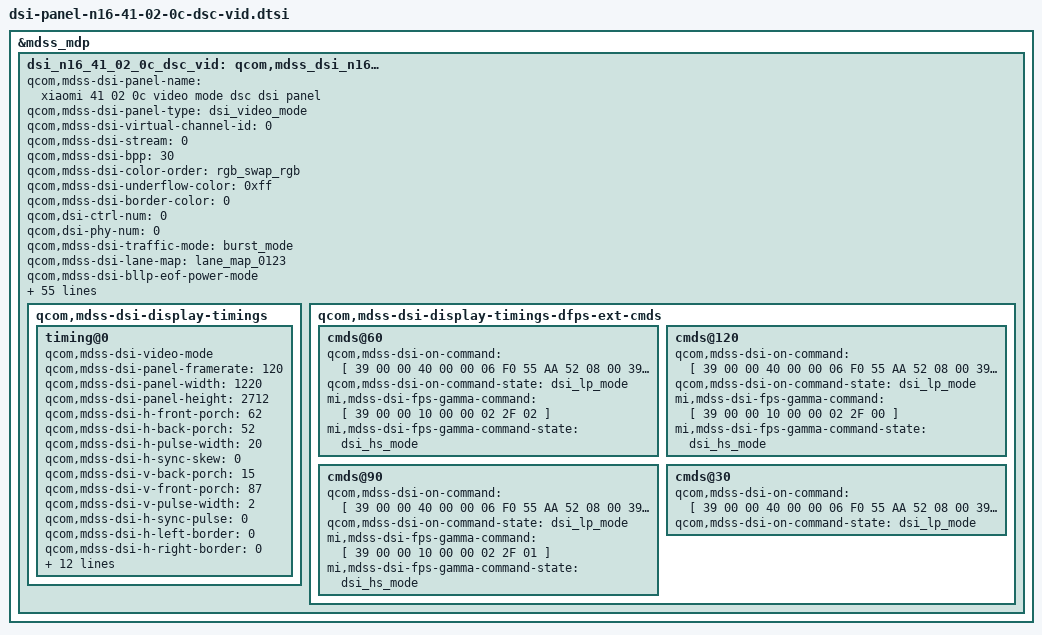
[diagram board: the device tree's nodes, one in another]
&mdss_mdp {
	dsi_n16_41_02_0c_dsc_vid: qcom,mdss_dsi_n16_41_02_0c_dsc_vid {
		qcom,mdss-dsi-panel-name = "xiaomi 41 02 0c video mode dsc dsi panel";
		qcom,mdss-dsi-panel-type = "dsi_video_mode";
		qcom,mdss-dsi-virtual-channel-id = <0>;
		qcom,mdss-dsi-stream = <0>;
		qcom,mdss-dsi-bpp = <30>;
		qcom,mdss-dsi-color-order = "rgb_swap_rgb";
		qcom,mdss-dsi-underflow-color = <0xff>;
		qcom,mdss-dsi-border-color = <0>;

		qcom,dsi-ctrl-num = <0>;
		qcom,dsi-phy-num = <0>;

		qcom,mdss-dsi-traffic-mode = "burst_mode";
		qcom,mdss-dsi-lane-map = "lane_map_0123";
		qcom,mdss-dsi-bllp-eof-power-mode;
		qcom,mdss-dsi-bllp-power-mode;
		qcom,mdss-dsi-lane-0-state;
		qcom,mdss-dsi-lane-1-state;
		qcom,mdss-dsi-lane-2-state;
		qcom,mdss-dsi-lane-3-state;
		qcom,mdss-dsi-dma-trigger = "trigger_sw";
		qcom,mdss-dsi-mdp-trigger = "none";
		qcom,mdss-dsi-reset-sequence =<1 11>, <0 1>, <1 11>;
		qcom,mdss-pan-physical-width-dimension = <70>;
		qcom,mdss-pan-physical-height-dimension = <154>;

		qcom,mdss-dsi-tx-eot-append;
		qcom,mdss-dsi-lp11-init;
		qcom,mdss-dsi-bl-inverted-dbv;
		qcom,bl-update-flag = "delay_until_first_frame";

		qcom,mdss-dsi-panel-hdr-enabled;
		qcom,mdss-dsi-panel-hdr-color-primaries = <14500 15500 32000 17000 15500 30000 8000 3000>;
		qcom,mdss-dsi-panel-peak-brightness = <4200000>;
		qcom,mdss-dsi-panel-blackness-level = <3230>;

		qcom,mdss-dsi-pan-enable-dynamic-fps;
		qcom,mdss-dsi-pan-fps-update =
				"dfps_immediate_porch_mode_vfp";
		qcom,dsi-supported-dfps-list = <60 120 90>;

		mi,mdss-dsi-panel-cell-id-read-command = [06 01 00 02 00 00 01 AC];
		mi,mdss-dsi-panel-cell-id-read-command-state = "dsi_hs_mode";
		mi,mdss-dsi-panel-cell-id-read-length = <18>;

		mi,mdss-dsi-panel-wp-read-command = [06 01 00 02 00 00 01 AC];
		mi,mdss-dsi-panel-wp-read-command-state = "dsi_hs_mode";
		mi,mdss-dsi-panel-wp-read-length = <3>;

        mi,mdss-dsi-panel-wp-read-pre-tx-command = [39 00 00 00 00 00 02 6F 18];
        mi,mdss-dsi-panel-wp-read-pre-tx-command-state = "dsi_hs_mode";

qcom,mdss-dsi-display-timings {
			timing@0{
				qcom,mdss-dsi-video-mode;
				qcom,mdss-dsi-panel-framerate = <120>;
				qcom,mdss-dsi-panel-width = <1220>;
				qcom,mdss-dsi-panel-height = <2712>;
				qcom,mdss-dsi-h-front-porch = <62>;
				qcom,mdss-dsi-h-back-porch = <52>;
				qcom,mdss-dsi-h-pulse-width = <20>;
				qcom,mdss-dsi-h-sync-skew = <0>;
				qcom,mdss-dsi-v-back-porch = <15>;
				qcom,mdss-dsi-v-front-porch = <87>;
				qcom,mdss-dsi-v-pulse-width = <2>;
				qcom,mdss-dsi-h-sync-pulse = <0>;
				qcom,mdss-dsi-h-left-border = <0>;
				qcom,mdss-dsi-h-right-border = <0>;
				qcom,mdss-dsi-v-top-border = <0>;
				qcom,mdss-dsi-v-bottom-border = <0>;

				qcom,compression-mode = "dsc";
				qcom,mdss-dsc-version = <0x12>;
				qcom,mdss-dsc-scr-version = <0x0>;
				qcom,mdss-dsc-slice-height = <12>;
				qcom,mdss-dsc-slice-width = <610>;
				qcom,mdss-dsc-slice-per-pkt = <2>;
				qcom,mdss-dsc-bit-per-component = <10>;
				qcom,mdss-dsc-bit-per-pixel = <8>;
				qcom,mdss-dsc-block-prediction-enable;
				qcom,mdss-dsi-panel-clockrate = <1098000000>;
			};
		};

qcom,mdss-dsi-display-timings-dfps-ext-cmds {
			cmds@60{
				qcom,mdss-dsi-on-command = [
					39 00 00 40 00 00 06 F0 55 AA 52 08 00
					39 00 00 40 00 00 02 6F 14
					39 00 00 40 00 00 1B B4 00 12 00 12 00 12 00 12 00 12 00 12 00 12 00 12 00 12 00 12 00 12 00 12 00 12
					39 00 00 40 00 00 02 6F 37
					39 00 00 00 00 00 04 DF 00 00 12
					39 00 00 40 00 00 05 FF AA 55 A5 80
					39 00 00 40 00 00 02 6F 18
					39 00 00 40 00 00 02 F4 73
					39 00 00 40 00 00 02 6F 2A
					39 00 00 40 00 00 02 F4 08
					39 00 00 40 00 00 02 6F 1A
					39 00 00 40 00 00 02 FE 00
					39 00 00 40 00 00 02 6F 46
					39 00 00 40 00 00 03 F4 07 09
					39 00 00 40 00 00 02 6F 4A
					39 00 00 40 00 00 03 F4 08 0A
					39 00 00 40 00 00 02 6F 56
					39 00 00 40 00 00 03 F4 44 44
					39 00 00 40 00 00 02 6F 0B
					39 00 00 00 00 00 02 F5 02
					39 00 00 40 00 00 06 F0 55 AA 52 08 08
					39 00 00 40 00 00 02 6F CE
					39 00 00 40 00 00 02 BC 01
					39 00 00 40 00 00 02 6F CF
					39 00 00 40 00 00 09 BC 01 11 00 B6 01 11 00 44
					39 00 00 00 00 00 02 E0 F3
					39 00 00 40 00 00 05 FF AA 55 A5 81
					39 00 00 40 00 00 02 6F 3C
					39 00 00 40 00 00 02 F5 87
					39 00 00 40 00 00 02 17 03
					39 00 00 40 00 00 02 71 00
					39 00 00 40 00 00 09 8D 00 00 04 C3 00 00 0A 97
					39 00 00 40 00 00 06 88 81 02 61 09 85
					39 00 00 40 00 00 05 2A 00 00 04 C3
					39 00 00 40 00 00 05 2B 00 00 0A 97
					39 00 00 40 00 00 02 03 00
					39 00 00 40 00 00 02 90 03
					39 00 00 40 00 00 02 6F 01
					39 00 00 40 00 00 02 90 43
					39 00 00 40 00 00 13 91 AB 28 00 0C C2 00 02 32 01 31 00 08 08 BB 07 7B 10 F0
					39 00 00 40 00 00 02 2F 02
					39 00 00 40 00 00 02 26 00
					39 00 00 40 00 00 03 5F 05 00
					39 00 00 40 00 00 02 53 20
					39 00 00 40 00 00 0D 3B 00 11 00 57 00 11 03 C7 00 11 0B 57
					39 00 00 40 00 00 02 6F 10
					39 00 00 40 00 00 05 3B 00 11 00 57
					39 00 00 40 00 00 02 35 00
					39 00 00 00 00 00 03 51 00 00
					39 00 00 40 00 00 06 F0 55 AA 52 08 00
					39 00 00 40 00 00 02 6F 13
					39 00 00 40 00 00 02 BE 45
					39 00 00 40 00 00 02 6F 19
					39 00 00 40 00 00 05 BE 10 91 00 AB
					39 00 00 40 00 00 02 6F 0D
					39 00 00 00 00 00 02 D8 02
					39 00 00 40 00 00 06 F0 55 AA 52 08 07
					15 00 00 40 00 00 02 C0 87
					15 00 00 40 00 00 02 6F 03
					39 00 00 00 00 00 0F C0 00 00 00 00 55 00 00 00 00 00 00 00 00 00
					39 00 00 00 78 00 02 11 00
					39 00 00 00 00 00 02 29 00
				];
				qcom,mdss-dsi-on-command-state = "dsi_lp_mode";

				mi,mdss-dsi-fps-gamma-command = [
					39 00 00 10 00 00 02 2F 02
				];
				mi,mdss-dsi-fps-gamma-command-state = "dsi_hs_mode";

				#include "dsi-panel-n16-41-02-0c-dsc-vid-common.dtsi"
			};
			cmds@120{
				qcom,mdss-dsi-on-command = [
					39 00 00 40 00 00 06 F0 55 AA 52 08 00
					39 00 00 40 00 00 02 6F 14
					39 00 00 40 00 00 1B B4 00 12 00 12 00 12 00 12 00 12 00 12 00 12 00 12 00 12 00 12 00 12 00 12 00 12
					39 00 00 40 00 00 02 6F 37
					39 00 00 00 00 00 04 DF 00 00 12
					39 00 00 40 00 00 05 FF AA 55 A5 80
					39 00 00 40 00 00 02 6F 18
					39 00 00 40 00 00 02 F4 73
					39 00 00 40 00 00 02 6F 2A
					39 00 00 40 00 00 02 F4 08
					39 00 00 40 00 00 02 6F 1A
					39 00 00 40 00 00 02 FE 00
					39 00 00 40 00 00 02 6F 46
					39 00 00 40 00 00 03 F4 07 09
					39 00 00 40 00 00 02 6F 4A
					39 00 00 40 00 00 03 F4 08 0A
					39 00 00 40 00 00 02 6F 56
					39 00 00 40 00 00 03 F4 44 44
					39 00 00 40 00 00 02 6F 0B
					39 00 00 00 00 00 02 F5 02
					39 00 00 40 00 00 06 F0 55 AA 52 08 08
					39 00 00 40 00 00 02 6F CE
					39 00 00 40 00 00 02 BC 01
					39 00 00 40 00 00 02 6F CF
					39 00 00 40 00 00 09 BC 01 11 00 B6 01 11 00 44
					39 00 00 00 00 00 02 E0 F3
					39 00 00 40 00 00 05 FF AA 55 A5 81
					39 00 00 40 00 00 02 6F 3C
					39 00 00 40 00 00 02 F5 87
					39 00 00 40 00 00 02 17 03
					39 00 00 40 00 00 02 71 00
					39 00 00 40 00 00 09 8D 00 00 04 C3 00 00 0A 97
					39 00 00 40 00 00 06 88 81 02 61 09 85
					39 00 00 40 00 00 05 2A 00 00 04 C3
					39 00 00 40 00 00 05 2B 00 00 0A 97
					39 00 00 40 00 00 02 03 00
					39 00 00 40 00 00 02 90 03
					39 00 00 40 00 00 02 6F 01
					39 00 00 40 00 00 02 90 43
					39 00 00 40 00 00 13 91 AB 28 00 0C C2 00 02 32 01 31 00 08 08 BB 07 7B 10 F0
					39 00 00 40 00 00 02 2F 00
					39 00 00 40 00 00 02 26 00
					39 00 00 40 00 00 03 5F 05 00
					39 00 00 40 00 00 02 53 20
					39 00 00 40 00 00 0D 3B 00 11 00 57 00 11 03 C7 00 11 0B 57
					39 00 00 40 00 00 02 6F 10
					39 00 00 40 00 00 05 3B 00 11 00 57
					39 00 00 40 00 00 02 35 00
					39 00 00 00 00 00 03 51 00 00
					39 00 00 40 00 00 06 F0 55 AA 52 08 00
					39 00 00 40 00 00 02 6F 13
					39 00 00 40 00 00 02 BE 45
					39 00 00 40 00 00 02 6F 19
					39 00 00 40 00 00 05 BE 10 91 00 AB
					39 00 00 40 00 00 02 6F 0D
					39 00 00 00 00 00 02 D8 02
					39 00 00 40 00 00 06 F0 55 AA 52 08 07 15 00 00 40 00 00 02 C0 87 15 00 00 40 00 00 02 6F 03
					39 00 00 00 00 00 0F C0 00 00 00 00 55 00 00 00 00 00 00 00 00 00
					39 00 00 00 78 00 02 11 00
					39 00 00 00 00 00 02 29 00
				];
				qcom,mdss-dsi-on-command-state = "dsi_lp_mode";

				mi,mdss-dsi-fps-gamma-command = [
					39 00 00 10 00 00 02 2F 00
				];
				mi,mdss-dsi-fps-gamma-command-state = "dsi_hs_mode";

				#include "dsi-panel-n16-41-02-0c-dsc-vid-common.dtsi"
			};
			cmds@90{
				qcom,mdss-dsi-on-command = [
					39 00 00 40 00 00 06 F0 55 AA 52 08 00
					39 00 00 40 00 00 02 6F 14
					39 00 00 40 00 00 1B B4 00 12 00 12 00 12 00 12 00 12 00 12 00 12 00 12 00 12 00 12 00 12 00 12 00 12
					39 00 00 40 00 00 02 6F 37
					39 00 00 00 00 00 04 DF 00 00 12
					39 00 00 40 00 00 05 FF AA 55 A5 80
					39 00 00 40 00 00 02 6F 18
					39 00 00 40 00 00 02 F4 73
					39 00 00 40 00 00 02 6F 2A
					39 00 00 40 00 00 02 F4 08
					39 00 00 40 00 00 02 6F 1A
					39 00 00 40 00 00 02 FE 00
					39 00 00 40 00 00 02 6F 46
					39 00 00 40 00 00 03 F4 07 09
					39 00 00 40 00 00 02 6F 4A
					39 00 00 40 00 00 03 F4 08 0A
					39 00 00 40 00 00 02 6F 56
					39 00 00 40 00 00 03 F4 44 44
					39 00 00 40 00 00 02 6F 0B
					39 00 00 00 00 00 02 F5 02
					39 00 00 40 00 00 06 F0 55 AA 52 08 08
					39 00 00 40 00 00 02 6F CE
					39 00 00 40 00 00 02 BC 01
					39 00 00 40 00 00 02 6F CF
					39 00 00 40 00 00 09 BC 01 11 00 B6 01 11 00 44
					39 00 00 00 00 00 02 E0 F3
					39 00 00 40 00 00 05 FF AA 55 A5 81
					39 00 00 40 00 00 02 6F 3C
					39 00 00 40 00 00 02 F5 87
					39 00 00 40 00 00 02 17 03
					39 00 00 40 00 00 02 71 00
					39 00 00 40 00 00 09 8D 00 00 04 C3 00 00 0A 97
					39 00 00 40 00 00 06 88 81 02 61 09 85
					39 00 00 40 00 00 05 2A 00 00 04 C3
					39 00 00 40 00 00 05 2B 00 00 0A 97
					39 00 00 40 00 00 02 03 00
					39 00 00 40 00 00 02 90 03
					39 00 00 40 00 00 02 6F 01
					39 00 00 40 00 00 02 90 43
					39 00 00 40 00 00 13 91 AB 28 00 0C C2 00 02 32 01 31 00 08 08 BB 07 7B 10 F0
					39 00 00 40 00 00 02 2F 01
					39 00 00 40 00 00 02 26 00
					39 00 00 40 00 00 03 5F 05 00
					39 00 00 40 00 00 02 53 20
					39 00 00 40 00 00 0D 3B 00 11 00 57 00 11 03 C7 00 11 0B 57
					39 00 00 40 00 00 02 6F 10
					39 00 00 40 00 00 05 3B 00 11 00 57
					39 00 00 40 00 00 02 35 00
					39 00 00 00 00 00 03 51 00 00
					39 00 00 40 00 00 06 F0 55 AA 52 08 00
					39 00 00 40 00 00 02 6F 13
					39 00 00 40 00 00 02 BE 45
					39 00 00 40 00 00 02 6F 19
					39 00 00 40 00 00 05 BE 10 91 00 AB
					39 00 00 40 00 00 02 6F 0D
					39 00 00 00 00 00 02 D8 02
					39 00 00 40 00 00 06 F0 55 AA 52 08 07
					15 00 00 40 00 00 02 C0 87
					15 00 00 40 00 00 02 6F 03
					39 00 00 00 00 00 0F C0 00 00 00 00 55 00 00 00 00 00 00 00 00 00
					39 00 00 00 78 00 02 11 00
					39 00 00 00 00 00 02 29 00
				];
				qcom,mdss-dsi-on-command-state = "dsi_lp_mode";

				mi,mdss-dsi-fps-gamma-command = [
					39 00 00 10 00 00 02 2F 01
				];
				mi,mdss-dsi-fps-gamma-command-state = "dsi_hs_mode";

				#include "dsi-panel-n16-41-02-0c-dsc-vid-common.dtsi"
			};
			cmds@30{
				qcom,mdss-dsi-on-command = [
					39 00 00 40 00 00 06 F0 55 AA 52 08 00
					39 00 00 40 00 00 02 6F 14
					39 00 00 40 00 00 1B B4 00 12 00 12 00 12 00 12 00 12 00 12 00 12 00 12 00 12 00 12 00 12 00 12 00 12
					39 00 00 40 00 00 02 6F 37
					39 00 00 00 00 00 04 DF 00 00 12
					39 00 00 40 00 00 05 FF AA 55 A5 80
					39 00 00 40 00 00 02 6F 18
					39 00 00 40 00 00 02 F4 73
					39 00 00 40 00 00 02 6F 2A
					39 00 00 40 00 00 02 F4 08
					39 00 00 40 00 00 02 6F 1A
					39 00 00 40 00 00 02 FE 00
					39 00 00 40 00 00 02 6F 46
					39 00 00 40 00 00 03 F4 07 09
					39 00 00 40 00 00 02 6F 4A
					39 00 00 40 00 00 03 F4 08 0A
					39 00 00 40 00 00 02 6F 56
					39 00 00 40 00 00 03 F4 44 44
					39 00 00 40 00 00 02 6F 0B
					39 00 00 00 00 00 02 F5 02
					39 00 00 40 00 00 06 F0 55 AA 52 08 08
					39 00 00 40 00 00 02 6F CE
					39 00 00 40 00 00 02 BC 01
					39 00 00 40 00 00 02 6F CF
					39 00 00 40 00 00 09 BC 01 11 00 B6 01 11 00 44
					39 00 00 00 00 00 02 E0 F3
					39 00 00 40 00 00 05 FF AA 55 A5 81
					39 00 00 40 00 00 02 6F 3C
					39 00 00 40 00 00 02 F5 87
					39 00 00 40 00 00 02 17 03
					39 00 00 40 00 00 02 71 00
					39 00 00 40 00 00 09 8D 00 00 04 C3 00 00 0A 97
					39 00 00 40 00 00 06 88 81 02 61 09 85
					39 00 00 40 00 00 05 2A 00 00 04 C3
					39 00 00 40 00 00 05 2B 00 00 0A 97
					39 00 00 40 00 00 02 03 00
					39 00 00 40 00 00 02 90 03
					39 00 00 40 00 00 02 6F 01
					39 00 00 40 00 00 02 90 43
					39 00 00 40 00 00 13 91 AB 28 00 0C C2 00 02 32 01 31 00 08 08 BB 07 7B 10 F0
					39 00 00 40 00 00 02 2F 00
					39 00 00 40 00 00 02 26 00
					39 00 00 40 00 00 03 5F 05 00
					39 00 00 40 00 00 02 53 20
					39 00 00 40 00 00 0D 3B 00 11 00 57 00 11 03 C7 00 11 0B 57
					39 00 00 40 00 00 02 6F 10
					39 00 00 40 00 00 05 3B 00 11 00 57
					39 00 00 40 00 00 02 35 00
					39 00 00 00 00 00 03 51 00 00
					39 00 00 40 00 00 06 F0 55 AA 52 08 00
					39 00 00 40 00 00 02 6F 13
					39 00 00 40 00 00 02 BE 45
					39 00 00 40 00 00 02 6F 19
					39 00 00 40 00 00 05 BE 10 91 00 AB
					39 00 00 40 00 00 02 6F 0D
					39 00 00 00 00 00 02 D8 02
					39 00 00 40 00 00 06 F0 55 AA 52 08 07
					15 00 00 40 00 00 02 C0 87
					15 00 00 40 00 00 02 6F 03
					39 00 00 00 00 00 0F C0 00 00 00 00 55 00 00 00 00 00 00 00 00 00
					39 00 00 00 78 00 02 11 00
					39 00 00 00 00 00 02 29 00
				];
				qcom,mdss-dsi-on-command-state = "dsi_lp_mode";

				#include "dsi-panel-n16-41-02-0c-dsc-vid-common.dtsi"
			};
		};
	};
};

&dsi_n16_41_02_0c_dsc_vid {
	mi,panel-id = <0x004E3136 0x00410203>;

	mi,max-brightness-clone = <16383>;
	mi,normal-max-brightness-clone = <4095>;
	mi,mdss-dsi-fac-bl-max-level = <2047>;
	mi,mdss-fac-brightness-max-level = <2047>;

	/* IRQF_ONESHOT | IRQF_TRIGGER_HIGH */
	mi,esd-err-irq-gpio = <&tlmm 65 0x2004>;
	mi,panel-ignore-esd-in-aod;

	mi,thermal-dimming-flag;
	mi,panel-on-dimming-delay = <120>;
	mi,dimming-need-update-speed;
	mi,dimming-node = <0 200 450 800 4095>;

	mi,doze-hbm-dbv-level = <262>;
	mi,doze-lbm-dbv-level = <25>;
	mi,ddic-round-corner-enabled;

	//use fps cmdsets
	mi,video-fps-cmdsets-flag;
	mi,local-hbm-enabled;
	mi,need-fod-animal-in-normal-enabled;
	mi,local-hbm-ui-ready-delay-num-frame = <3>; /* 3 frame */
};
